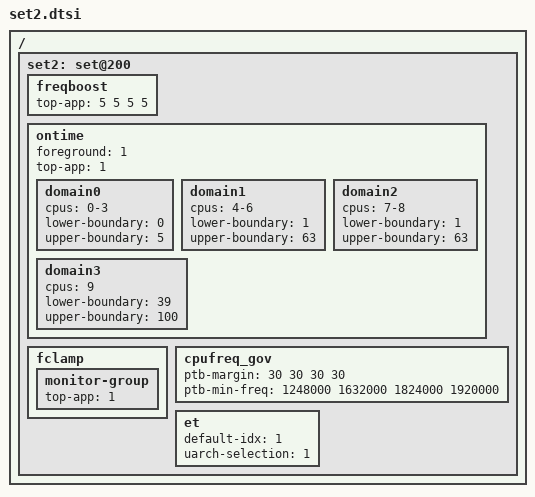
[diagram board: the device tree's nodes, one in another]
/ {
	/* performance mode - default */
	set2: set@200 {
		/* Boosting margin applied to frequency selection */
		freqboost {			/* LIT MED-L MED-H BIG */
			top-app			= <  5   5   5   5>;
		};

		/* Ontime Migration */
		ontime {
			foreground 	= <1>;
			top-app		= <1>;

			domain0 {
				cpus = "0-3";
				lower-boundary = <0>;
				upper-boundary = <5>;
			};
			domain1 {
				cpus = "4-6";
				lower-boundary = <1>;
				upper-boundary = <63>;
			};
			domain2 {
				cpus = "7-8";
				lower-boundary = <1>;
				upper-boundary = <63>;
			};
			domain3 {
				cpus = "9";
				lower-boundary = <39>;
				upper-boundary = <100>;
			};
		};

		fclamp {
			monitor-group {
				top-app         = <1>;
			};
		};

		cpufreq_gov {
				/* LIT MED-L MED-H BIG */
			ptb-margin = < 30 30 30 30 >;
			ptb-min-freq = < 1248000 1632000 1824000 1920000 >;
		};

		et {
			default-idx = < 1 >;
			uarch-selection = < 1 >;
		};
	};
};
